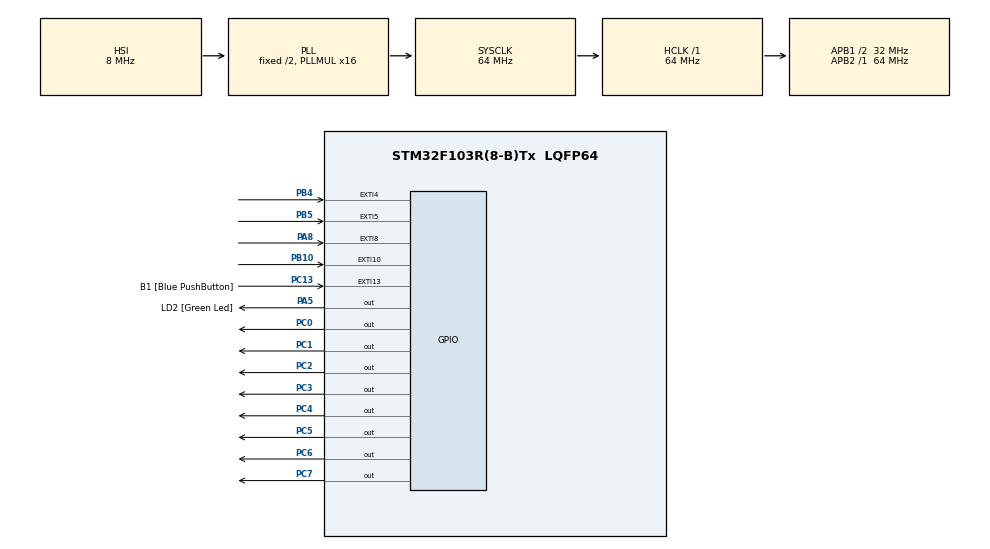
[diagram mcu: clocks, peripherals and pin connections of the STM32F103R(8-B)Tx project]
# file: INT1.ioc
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Mcu.Family=STM32F1
Mcu.Name=STM32F103R(8-B)Tx
Mcu.Package=LQFP64
NVIC.EXTI15_10_IRQn=true\:0\:0\:false\:false\:true\:true\:true\:true
NVIC.EXTI4_IRQn=true\:0\:0\:false\:false\:true\:true\:true\:true
NVIC.EXTI9_5_IRQn=true\:0\:0\:false\:false\:true\:true\:true\:true
NVIC.PriorityGroup=NVIC_PRIORITYGROUP_4
PA5.GPIO_Label=LD2 [Green Led]
PA5.GPIO_ModeDefaultOutputPP=GPIO_MODE_OUTPUT_PP
PA5.GPIO_PuPd=GPIO_NOPULL
PA5.GPIO_Speed=GPIO_SPEED_FREQ_LOW
PA5.Signal=GPIO_Output
PA8.Signal=GPXTI8
PB10.Signal=GPXTI10
PB4.Signal=GPXTI4
PB5.Signal=GPXTI5
PC0.Signal=GPIO_Output
PC1.Signal=GPIO_Output
PC13-TAMPER-RTC.GPIO_Label=B1 [Blue PushButton]
PC13-TAMPER-RTC.GPIO_PuPd=GPIO_NOPULL
PC13-TAMPER-RTC.Signal=GPXTI13
PC2.Signal=GPIO_Output
PC3.Signal=GPIO_Output
PC4.Signal=GPIO_Output
PC5.Signal=GPIO_Output
PC6.Signal=GPIO_Output
PC7.Signal=GPIO_Output
ProjectManager.HeapSize=0x200
ProjectManager.StackSize=0x400
ProjectManager.TargetToolchain=STM32CubeIDE
RCC.AHBFreq_Value=64000000
RCC.APB1CLKDivider=RCC_HCLK_DIV2
RCC.APB1Freq_Value=32000000
RCC.APB1TimFreq_Value=64000000
RCC.APB2Freq_Value=64000000
RCC.APB2TimFreq_Value=64000000
RCC.HCLKFreq_Value=64000000
RCC.PLLMUL=RCC_PLL_MUL16
RCC.RTCClockSelection=RCC_RTCCLKSOURCE_LSE
RCC.SYSCLKFreq_VALUE=64000000
RCC.SYSCLKSource=RCC_SYSCLKSOURCE_PLLCLK
RCC.USBFreq_Value=64000000
VP_SYS_VS_ND.Mode=No_Debug
board=NUCLEO-F103RB

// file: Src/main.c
/* USER CODE BEGIN Header */
/**
 ******************************************************************************
 * @file           : main.c
 * @brief          : Main program body
 ******************************************************************************
 * @attention
 *
 * Copyright (c) 2024 STMicroelectronics.
 * All rights reserved.
 *
 * This software is licensed under terms that can be found in the LICENSE file
 * in the root directory of this software component.
 * If no LICENSE file comes with this software, it is provided AS-IS.
 *
 ******************************************************************************
 */
/* USER CODE END Header */
#include "main.h"

/* USER CODE BEGIN PV */
int flag_sw1 = 0;
/* USER CODE END PV */

void SystemClock_Config(void);
static void MX_GPIO_Init(void);
/* USER CODE BEGIN PFP */
void HAL_GPIO_EXTI_Callback(uint16_t GPIO_Pin) {
	if (GPIO_Pin == B1_Pin)
		flag_sw1 = 1;
	if (GPIO_Pin == GPIO_PIN_8)
		flag_sw1 = 1;
}
void LED_OnOff(int led, int delay) {
	HAL_GPIO_WritePin(GPIOC, led, GPIO_PIN_SET);
	HAL_Delay(delay);
	HAL_GPIO_WritePin(GPIOC, led, GPIO_PIN_RESET);
}
/* USER CODE END PFP */

int main(void) {

	/* USER CODE BEGIN 1 */
	uint16_t led = GPIO_PIN_0 | GPIO_PIN_1 | GPIO_PIN_2 | GPIO_PIN_3
			| GPIO_PIN_4 | GPIO_PIN_5 | GPIO_PIN_6 | GPIO_PIN_7;
	/* USER CODE END 1 */

	/* MCU Configuration--------------------------------------------------------*/

	/* Reset of all peripherals, Initializes the Flash interface and the Systick. */
	HAL_Init();

	/* Configure the system clock */
	SystemClock_Config();

	/* Initialize all configured peripherals */
	MX_GPIO_Init();

	/* Infinite loop */
	while (1) {
		if (flag_sw1 == 1) {
			LED_OnOff(led, 500);
			flag_sw1 = 0;
		}
	}
}

void SystemClock_Config(void) {
	RCC_OscInitTypeDef RCC_OscInitStruct = { 0 };
	RCC_ClkInitTypeDef RCC_ClkInitStruct = { 0 };

	/** Initializes the RCC Oscillators according to the specified parameters
	 * in the RCC_OscInitTypeDef structure.
	 */
	RCC_OscInitStruct.OscillatorType = RCC_OSCILLATORTYPE_HSI;
	RCC_OscInitStruct.HSIState = RCC_HSI_ON;
	RCC_OscInitStruct.HSICalibrationValue = RCC_HSICALIBRATION_DEFAULT;
	RCC_OscInitStruct.PLL.PLLState = RCC_PLL_ON;
	RCC_OscInitStruct.PLL.PLLSource = RCC_PLLSOURCE_HSI_DIV2;
	RCC_OscInitStruct.PLL.PLLMUL = RCC_PLL_MUL16;
	if (HAL_RCC_OscConfig(&RCC_OscInitStruct) != HAL_OK) {
		Error_Handler();
	}

	/** Initializes the CPU, AHB and APB buses clocks
	 */
	RCC_ClkInitStruct.ClockType = RCC_CLOCKTYPE_HCLK | RCC_CLOCKTYPE_SYSCLK
			| RCC_CLOCKTYPE_PCLK1 | RCC_CLOCKTYPE_PCLK2;
	RCC_ClkInitStruct.SYSCLKSource = RCC_SYSCLKSOURCE_PLLCLK;
	RCC_ClkInitStruct.AHBCLKDivider = RCC_SYSCLK_DIV1;
	RCC_ClkInitStruct.APB1CLKDivider = RCC_HCLK_DIV2;
	RCC_ClkInitStruct.APB2CLKDivider = RCC_HCLK_DIV1;

	if (HAL_RCC_ClockConfig(&RCC_ClkInitStruct, FLASH_LATENCY_2) != HAL_OK) {
		Error_Handler();
	}
}

static void MX_GPIO_Init(void) {
	GPIO_InitTypeDef GPIO_InitStruct = { 0 };

	/* GPIO Ports Clock Enable */
	__HAL_RCC_GPIOC_CLK_ENABLE();
	__HAL_RCC_GPIOA_CLK_ENABLE();
	__HAL_RCC_GPIOB_CLK_ENABLE();

	/*Configure GPIO pin Output Level */
	HAL_GPIO_WritePin(GPIOC,
			GPIO_PIN_0 | GPIO_PIN_1 | GPIO_PIN_2 | GPIO_PIN_3 | GPIO_PIN_4
					| GPIO_PIN_5 | GPIO_PIN_6 | GPIO_PIN_7, GPIO_PIN_RESET);

	/*Configure GPIO pin Output Level */
	HAL_GPIO_WritePin(LD2_GPIO_Port, LD2_Pin, GPIO_PIN_RESET);

	/*Configure GPIO pin : B1_Pin */
	GPIO_InitStruct.Pin = B1_Pin;
	GPIO_InitStruct.Mode = GPIO_MODE_IT_RISING;
	GPIO_InitStruct.Pull = GPIO_NOPULL;
	HAL_GPIO_Init(B1_GPIO_Port, &GPIO_InitStruct);

	/*Configure GPIO pins : PC0 PC1 PC2 PC3
	 PC4 PC5 PC6 PC7 */
	GPIO_InitStruct.Pin = GPIO_PIN_0 | GPIO_PIN_1 | GPIO_PIN_2 | GPIO_PIN_3
			| GPIO_PIN_4 | GPIO_PIN_5 | GPIO_PIN_6 | GPIO_PIN_7;
	GPIO_InitStruct.Mode = GPIO_MODE_OUTPUT_PP;
	GPIO_InitStruct.Pull = GPIO_NOPULL;
	GPIO_InitStruct.Speed = GPIO_SPEED_FREQ_LOW;
	HAL_GPIO_Init(GPIOC, &GPIO_InitStruct);

	/*Configure GPIO pin : LD2_Pin */
	GPIO_InitStruct.Pin = LD2_Pin;
	GPIO_InitStruct.Mode = GPIO_MODE_OUTPUT_PP;
	GPIO_InitStruct.Pull = GPIO_NOPULL;
	GPIO_InitStruct.Speed = GPIO_SPEED_FREQ_LOW;
	HAL_GPIO_Init(LD2_GPIO_Port, &GPIO_InitStruct);

	/*Configure GPIO pins : PB10 PB4 PB5 */
	GPIO_InitStruct.Pin = GPIO_PIN_10 | GPIO_PIN_4 | GPIO_PIN_5;
	GPIO_InitStruct.Mode = GPIO_MODE_IT_RISING;
	GPIO_InitStruct.Pull = GPIO_NOPULL;
	HAL_GPIO_Init(GPIOB, &GPIO_InitStruct);

	/*Configure GPIO pin : PA8 */
	GPIO_InitStruct.Pin = GPIO_PIN_8;
	GPIO_InitStruct.Mode = GPIO_MODE_IT_RISING;
	GPIO_InitStruct.Pull = GPIO_NOPULL;
	HAL_GPIO_Init(GPIOA, &GPIO_InitStruct);

	/* EXTI interrupt init*/
	HAL_NVIC_SetPriority(EXTI4_IRQn, 0, 0);
	HAL_NVIC_EnableIRQ(EXTI4_IRQn);

	HAL_NVIC_SetPriority(EXTI9_5_IRQn, 0, 0);
	HAL_NVIC_EnableIRQ(EXTI9_5_IRQn);

	HAL_NVIC_SetPriority(EXTI15_10_IRQn, 0, 0);
	HAL_NVIC_EnableIRQ(EXTI15_10_IRQn);

}

void Error_Handler(void) {
	__disable_irq();
	while (1) {
	}
}
